# ADC1 register map
Vendor: Texas Instruments
Peripheral module from a debugger description file (folder am437x).
Registers are 32-bit, access per field, no defined reset value unless marked. A register's access mark holds for its fields unless they carry their own. Offsets are as the file gives them; lines under a group give offsets from that group; [hi:lo] are bit positions; {n}, {i} and the like mark numbered series; 'fields as' and 'values as' point back to an identical list; <NAME> marks a mode.

## ADC1
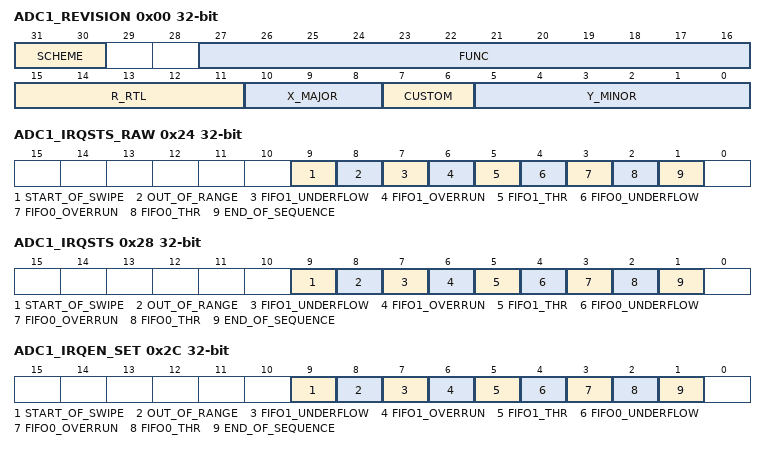
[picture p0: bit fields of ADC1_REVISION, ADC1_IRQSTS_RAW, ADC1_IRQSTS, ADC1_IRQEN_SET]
0x00 ADC1_REVISION ro
  [31:30] SCHEME — HL 0.8 scheme
  [27:16] FUNC — Functional Number
  [15:11] R_RTL — RTL revision. [[br]]Will vary depending on release.
  [10:8] X_MAJOR — Major revision.
  [7:6] CUSTOM — Custom revision.
  [5:0] Y_MINOR — Minor revision
0x10 ADC1_SYSCONFIG
  [3:2] IDLEMODE rw — [[br]]00 -> Force Idle (always acknowledges). [[br]]01 -> No Idle Mode (never acknowledges). [[br]]10 -> Smart-Idle Mode. [[br]]11 -> Reserved.
0x24 ADC1_IRQSTS_RAW
  [9] START_OF_SWIPE rw — [[br]]Write 0: No action. [[br]]Write 1: Set event (debug). [[br]]Read 0: No event pending. [[br]]Read 1: Event pending.
  [8] OUT_OF_RANGE rw — [[br]]Write 0: No action. [[br]]Write 1: Set event (debug). [[br]]Read 0: No event pending. [[br]]Read 1: Event pending.
  [7] FIFO1_UNDERFLOW rw — [[br]]Write 0: No action. [[br]]Write 1: Set event (debug). [[br]]Read 0: No event pending. [[br]]Read 1: Event pending.
  [6] FIFO1_OVERRUN rw — [[br]]Write 0: No action. [[br]]Write 1: Set event (debug). [[br]]Read 0: No event pending. [[br]]Read 1: Event pending.
  [5] FIFO1_THR rw — [[br]]Write 0: No action. [[br]]Write 1: Set event (debug). [[br]]Read 0: No event pending. [[br]]Read 1: Event pending.
  [4] FIFO0_UNDERFLOW rw — [[br]]Write 0: No action. [[br]]Write 1: Set event (debug). [[br]]Read 0: No event pending. [[br]]Read 1: Event pending.
  [3] FIFO0_OVERRUN rw — [[br]]Write 0: No action. [[br]]Write 1: Set event (debug). [[br]]Read 0: No event pending. [[br]]Read 1: Event pending.
  [2] FIFO0_THR rw — [[br]]Write 0: No action. [[br]]Write 1: Set event (debug). [[br]]Read 0: No event pending. [[br]]Read 1: Event pending.
  [1] END_OF_SEQUENCE rw — [[br]]Write 0: No action. [[br]]Write 1: Set event (debug). [[br]]Read 0: No event pending. [[br]]Read 1: Event pending.
0x28 ADC1_IRQSTS
  [9] START_OF_SWIPE rw — [[br]]Write 0: No action. [[br]]Read 0: No (enabled) event pending. [[br]]Read 1: Event pending. [[br]]Write 1: Clear (raw) event.
  [8] OUT_OF_RANGE rw — [[br]]Write 0: No action. [[br]]Read 0: No (enabled) event pending. [[br]]Read 1: Event pending. [[br]]Write 1: Clear (raw) event.
  [7] FIFO1_UNDERFLOW rw — [[br]]Write 0: No action. [[br]]Read 0: No (enabled) event pending. [[br]]Read 1: Event pending. [[br]]Write 1: Clear (raw) event.
  [6] FIFO1_OVERRUN rw — [[br]]Write 0: No action. [[br]]Read 0: No (enabled) event pending. [[br]]Read 1: Event pending. [[br]]Write 1: Clear (raw) event.
  [5] FIFO1_THR rw — [[br]]Write 0: No action. [[br]]Read 0: No (enabled) event pending. [[br]]Read 1: Event pending. [[br]]Write 1: Clear (raw) event.
  [4] FIFO0_UNDERFLOW rw — [[br]]Write 0: No action. [[br]]Read 0: No (enabled) event pending. [[br]]Read 1: Event pending. [[br]]Write 1: Clear (raw) event.
  [3] FIFO0_OVERRUN rw — [[br]]Write 0: No action. [[br]]Read 0: No (enabled) event pending. [[br]]Read 1: Event pending. [[br]]Write 1: Clear (raw) event.
  [2] FIFO0_THR rw — [[br]]Write 0: No action. [[br]]Read 0: No (enabled) event pending. [[br]]Read 1: Event pending. [[br]]Write 1: Clear (raw) event.
  [1] END_OF_SEQUENCE rw — [[br]]Write 0: No action. [[br]]Read 0: No (enabled) event pending. [[br]]Read 1: Event pending. [[br]]Write 1: Clear (raw) event.
0x2C ADC1_IRQEN_SET
  [9] START_OF_SWIPE rw — [[br]]Write 0: No action. [[br]]Read 0: Interrupt disabled (masked). [[br]]Read 1: Interrupt enabled. [[br]]Write 1: Enable interrupt.
  [8] OUT_OF_RANGE rw — [[br]]Write 0: No action. [[br]]Read 0: Interrupt disabled (masked). [[br]]Read 1: Interrupt enabled. [[br]]Write 1: Enable interrupt.
  [7] FIFO1_UNDERFLOW rw — [[br]]Write 0: No action. [[br]]Read 0: Interrupt disabled (masked). [[br]]Read 1: Interrupt enabled. [[br]]Write 1: Enable interrupt.
  [6] FIFO1_OVERRUN rw — [[br]]Write 0: No action. [[br]]Read 0: Interrupt disabled (masked). [[br]]Read 1: Interrupt enabled. [[br]]Write 1: Enable interrupt.
  [5] FIFO1_THR rw — [[br]]Write 0: No action. [[br]]Read 0: Interrupt disabled (masked). [[br]]Read 1: Interrupt enabled. [[br]]Write 1: Enable interrupt.
  [4] FIFO0_UNDERFLOW rw — [[br]]Write 0: No action. [[br]]Read 0: Interrupt disabled (masked). [[br]]Read 1: Interrupt enabled. [[br]]Write 1: Enable interrupt.
  [3] FIFO0_OVERRUN rw — [[br]]Write 0: No action. [[br]]Read 0: Interrupt disabled (masked). [[br]]Read 1: Interrupt enabled. [[br]]Write 1: Enable interrupt.
  [2] FIFO0_THR rw — [[br]]Write 0: No action. [[br]]Read 0: Interrupt disabled (masked). [[br]]Read 1: Interrupt enabled. [[br]]Write 1: Enable interrupt.
  [1] END_OF_SEQUENCE rw — [[br]]Write 0: No action. [[br]]Read 0: Interrupt disabled (masked). [[br]]Read 1: Interrupt enabled. [[br]]Write 1: Enable interrupt.
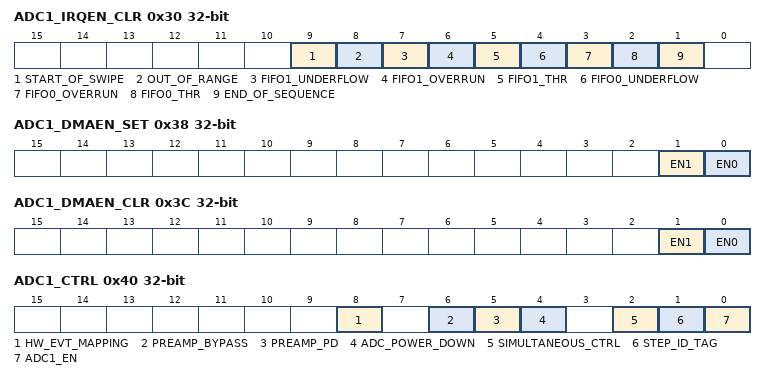
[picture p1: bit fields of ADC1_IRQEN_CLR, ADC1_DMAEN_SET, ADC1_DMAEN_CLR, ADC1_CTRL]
0x30 ADC1_IRQEN_CLR
  [9] START_OF_SWIPE rw — [[br]]Write 0: No action. [[br]]Read 0: Interrupt disabled (masked). [[br]]Read 1: Interrupt enabled. [[br]]Write 1: Disable interrupt.
  [8] OUT_OF_RANGE rw — [[br]]Write 0: No action. [[br]]Read 0: Interrupt disabled (masked). [[br]]Read 1: Interrupt enabled. [[br]]Write 1: Disable interrupt.
  [7] FIFO1_UNDERFLOW rw — [[br]]Write 0: No action. [[br]]Read 0: Interrupt disabled (masked). [[br]]Read 1: Interrupt enabled. [[br]]Write 1: Disable interrupt.
  [6] FIFO1_OVERRUN rw — [[br]]Write 0: No action. [[br]]Read 0: Interrupt disabled (masked). [[br]]Read 1: Interrupt enabled. [[br]]Write 1: Disable interrupt.
  [5] FIFO1_THR rw — [[br]]Write 0: No action. [[br]]Read 0: Interrupt disabled (masked). [[br]]Read 1: Interrupt enabled. [[br]]Write 1: Disable interrupt.
  [4] FIFO0_UNDERFLOW rw — [[br]]Write 0: No action. [[br]]Read 0: Interrupt disabled (masked). [[br]]Read 1: Interrupt enabled. [[br]]Write 1: Disable interrupt.
  [3] FIFO0_OVERRUN rw — [[br]]Write 0: No action. [[br]]Read 0: Interrupt disabled (masked). [[br]]Read 1: Interrupt enabled. [[br]]Write 1: Disable interrupt.
  [2] FIFO0_THR rw — [[br]]Write 0: No action. [[br]]Read 0: Interrupt disabled (masked). [[br]]Read 1: Interrupt enabled. [[br]]Write 1: Disable interrupt.
  [1] END_OF_SEQUENCE rw — [[br]]Write 0: No action. [[br]]Read 0: Interrupt disabled (masked). [[br]]Read 1: Interrupt enabled. [[br]]Write 1: Disable interrupt.
0x38 ADC1_DMAEN_SET rw
  [1] EN1 — Enable DMA request FIFO1. [[br]]Write 0: No action. [[br]]Read 0: DMA line disabled. [[br]]Read 1: DMA line enabled. [[br]]Write 1: Enable DMA line.
  [0] EN0 — Enable DMA request FIFO0. [[br]]Write 0: No action. [[br]]Read 0: DMA line disabled. [[br]]Read 1: DMA line enabled. [[br]]Write 1: Enable DMA line.
0x3C ADC1_DMAEN_CLR rw
  [1] EN1 — Disable DMA request FIFO1. [[br]]Write 0: No action. [[br]]Read 0: DMA line disabled. [[br]]Read 1: DMA line enabled. [[br]]Write 1: Disable DMA line.
  [0] EN0 — Disable DMA request FIFO0. [[br]]Write 0 : No action. [[br]]Read 0 : DMA line disabled. [[br]]Read 1: DMA line enabled. [[br]]Write 1: Disable DMA line.
0x40 ADC1_CTRL
  [8] HW_EVT_MAPPING rw — [[br]]0->Map hardware event to the start of swipe interrupt. [[br]]1->Map hardware event to hardware event input (external).
  [6] PREAMP_BYPASS rw — Analog input will bypass the PreAmplifier: 0: PreAmp is enabled by default. [[br]]1 : Write 1 to bypass PreAmp.
  [5] PREAMP_PD rw — PreAmp Power Down control. [[br]]0: PreAmp is powered up (default). [[br]]1 : Write 1 to power down PreAmp.
  [4] ADC_POWER_DOWN rw — ADC Power Down control. [[br]]0: AFE is powered up (default). [[br]]1 : Write 1 to power down AFE.
  [2] SIMULTANEOUS_CTRL rw — Enables Simultaneous Control of both AFEs. [[br]]0 -> Control only MCR_AFE. [[br]]1 -> Control both MCR_AFE and TSC_AFE. [[br]]See the Programmers/Usage guide section for Simultaneous Mode Features/Limitations.
  [1] STEP_ID_TAG rw — Writing 1 to this bit will store the Step ID number with the captured ADC data in the FIFO. [[br]]0: Write zeros. [[br]]1: Store the channel ID tag.
  [0] ADC1_EN rw — ADC1 module enable bit. [[br]]After programming all the steps and configuration registers, write a 1 to this bit to turn on ADC1. [[br]]Writing a 0 will disable the module (after the current conversion is completed).
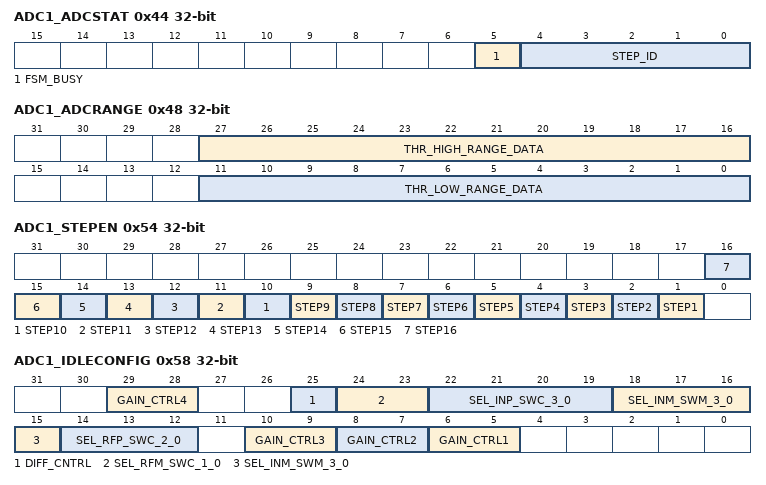
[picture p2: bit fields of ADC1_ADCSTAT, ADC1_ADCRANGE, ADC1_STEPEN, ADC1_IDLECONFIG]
0x44 ADC1_ADCSTAT ro
  [5] FSM_BUSY — Status of OCP FSM and ADC FSM. [[br]]0 idle. [[br]]1 - busy.
  [4:0] STEP_ID — Below are encoded values: 10000 Idle. [[br]]10001 Reserved. [[br]]00000 Step 1. [[br]]00001 Step 2. [[br]]00010 Step 3. [[br]]00011 Step 4. [[br]]00100 Step 5. [[br]]00101 Step 6. [[br]]00110 Step 7. [[br]]00111 Step 8. [[br]]01000 Step 9. [[br]]01001 Step 10. [[br]]01010 Step 11. [[br]]01011 Step 12. [[br]]01100 Step 13. [[br]]01101 Step 14. [[br]]01110 Step 15. [[br]]01111 Step 16.
0x48 ADC1_ADCRANGE
  [27:16] THR_HIGH_RANGE_DATA rw — Sampled ADC data is compared to this value. [[br]]If the interrupt is enabled, and if the sampled data is > value then interrupt is generated. [[br]]Each step can enable or disable this check.
  [11:0] THR_LOW_RANGE_DATA rw — Sampled ADC data is compared to this value. [[br]]If the interrupt is enabled, and if the sampled data is < value then interrupt is generated. [[br]]Each step can enable or disable this check.
0x4C ADC1_CLKDIV 16-bit rw
  [15:0] ADC_CLKDIV — The input ADC clock will be divided by this value and sent to the AFE. [[br]]Program to the value minus 1.
0x54 ADC1_STEPEN
  [n] STEP{n} rw (n=1..16) — Enable step {n}.
0x58 ADC1_IDLECONFIG
  [29:28] GAIN_CTRL4 rw — [[br]]00: Gain of 12. [[br]]01: Gain of 14. [[br]]10: Gain of 16. [[br]]11: Gain of 18.
  [25] DIFF_CNTRL rw — Differential Control Pin. [[br]]0 -> Single Ended. [[br]]1 -> Differential Pair Enable.
  [24:23] SEL_RFM_SWC_1_0 rw — SEL_RFM pins software configuration. [[br]]00 - VSSA. [[br]]01 - VSSA. [[br]]10 - VSSA. [[br]]11 ADCREFM.
  [22:19] SEL_INP_SWC_3_0 rw — SEL_INP pins software configuration. [[br]]0000 -> Channel 1. [[br]]0111 -> Channel 8. [[br]]1xxx -> ADCREFM.
  [18:15] SEL_INM_SWM_3_0 rw — SEL_INM pins for neg differential. [[br]]0000 -> Channel 1. [[br]]0111 -> Channel 8. [[br]]1xxx -> ADCREFM.
  [14:12] SEL_RFP_SWC_2_0 rw — SEL_RFP pins software configuration. [[br]]000 - VDDA. [[br]]001 - VDDA. [[br]]010 - VDDA. [[br]]011 - ADCREFP. [[br]]1xx - Reserved.
  [10:9] GAIN_CTRL3 rw — [[br]]00: Gain of 12. [[br]]01: Gain of 14. [[br]]10: Gain of 16. [[br]]11: Gain of 18.
  [8:7] GAIN_CTRL2 rw — [[br]]00: Gain of 12. [[br]]01: Gain of 14. [[br]]10: Gain of 16. [[br]]11: Gain of 18.
  [6:5] GAIN_CTRL1 rw — [[br]]00: Gain of 12. [[br]]01: Gain of 14. [[br]]10: Gain of 16. [[br]]11: Gain of 18.
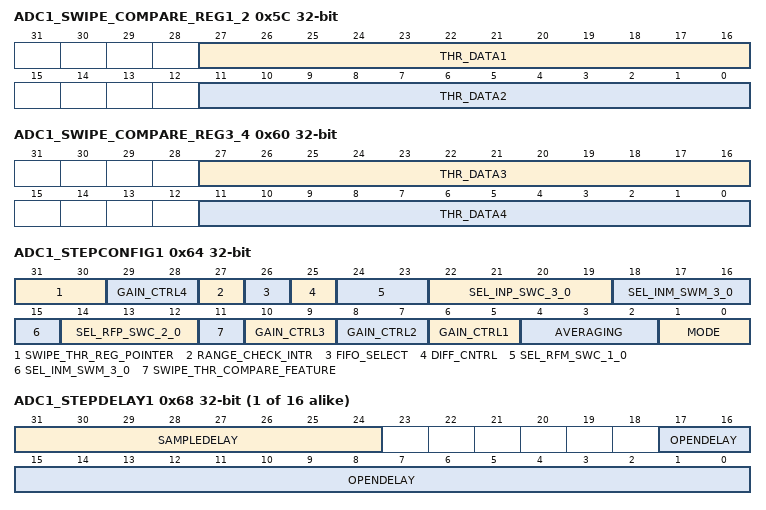
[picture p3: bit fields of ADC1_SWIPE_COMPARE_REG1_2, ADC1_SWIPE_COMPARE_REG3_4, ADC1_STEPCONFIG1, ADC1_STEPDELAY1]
0x5C ADC1_SWIPE_COMPARE_REG1_2
  [27:16] THR_DATA1 rw — Sampled ADC data is compared to this value. [[br]]If the swipe feature is enabled, and if the sampled data is >= value then data is saved in the FIFO (and also subsequent data is saved for all steps). [[br]]
  [11:0] THR_DATA2 rw — Sampled ADC data is compared to this value. [[br]]If the swipe feature is enabled, and if the sampled data is >= value then data is saved in the FIFO (and also subsequent data is saved for all steps). [[br]]
0x60 ADC1_SWIPE_COMPARE_REG3_4
  [27:16] THR_DATA3 rw — Sampled ADC data is compared to this value. [[br]]If the swipe feature is enabled, and if the sampled data is >= value then data is saved in the FIFO (and also subsequent data is saved for all steps). [[br]]
  [11:0] THR_DATA4 rw — Sampled ADC data is compared to this value. [[br]]If the swipe feature is enabled, and if the sampled data is >= value then data is saved in the FIFO (and also subsequent data is saved for all steps). [[br]]
0x64 ADC1_STEPCONFIG1 rw
  [31:30] SWIPE_THR_REG_POINTER — If the Swipe Data Compare feature is enabled (refer to bit 11) then: 00 Trigger using swipe threshold reg1. [[br]]01 Trigger using swipe threshold reg 2. [[br]]10 Trigger using swipe threshold reg 3. [[br]]11 Trigger using swipe threshold reg 4.
  [29:28] GAIN_CTRL4 — [[br]]00: Gain of 12. [[br]]01: Gain of 14. [[br]]10: Gain of 16. [[br]]11: Gain of 18.
  [27] RANGE_CHECK_INTR — [[br]]0 - disable out of range check. [[br]]1 - Compare adc data with range check register.
  [26] FIFO_SELECT — Sampled data will be stored in FIFO: [[br]]0 -> FIFO 0. [[br]]1 -> FIFO 1.
  [25] DIFF_CNTRL — Differential Control Pin. [[br]]0 -> Single Ended. [[br]]1 -> Differential Pair Enable.
  [24:23] SEL_RFM_SWC_1_0 — SEL_RFM pins software configuration. [[br]]00 - VSSA. [[br]]01 - VSSA. [[br]]10 - VSSA. [[br]]11 ADCREFM.
  [22:19] SEL_INP_SWC_3_0 — SEL_INP pins software configuration. [[br]]0000 -> Channel 1. [[br]]0111 -> Channel 8. [[br]]1xxx -> ADCREFM.
  [18:15] SEL_INM_SWM_3_0 — SEL_INM pins for neg differential. [[br]]0000 -> Channel 1. [[br]]0111 -> Channel 8. [[br]]1xxx -> ADCREFM.
  [14:12] SEL_RFP_SWC_2_0 — SEL_RFP pins software configuration. [[br]]000 - VDDA. [[br]]001 - VDDA. [[br]]010 - VDDA. [[br]]011 - ADCREFP. [[br]]1xx - Reserved.
  [11] SWIPE_THR_COMPARE_FEATURE — Set this bit to 1 to enable the swipe data comparing feature: [[br]]0: Feature is off (data is always saved). [[br]]1: Trigger feature is on [[br]] if adc data < swipe data threshold map pointer value then discard data[[br]] otherwise data is saved (and all future steps are saved) until mag_adc enable (bit 0) is turned off.
  [10:9] GAIN_CTRL3 — [[br]]00: Gain of 12. [[br]]01: Gain of 14. [[br]]10: Gain of 16. [[br]]11: Gain of 18.
  [8:7] GAIN_CTRL2 — [[br]]00: Gain of 12. [[br]]01: Gain of 14. [[br]]10: Gain of 16. [[br]]11: Gain of 18.
  [6:5] GAIN_CTRL1 — [[br]]00: Gain of 12. [[br]]01: Gain of 14. [[br]]10: Gain of 16. [[br]]11: Gain of 18.
  [4:2] AVERAGING — Number of samplings to average: [[br]]000 -> no average. [[br]]001 -> 2 samples average. [[br]]010 -> 4 samples average. [[br]]011 -> 8 samples average. [[br]]100 -> 16 samples average.
  [1:0] MODE — 00 Software enabled, one-shot. [[br]]01 Software enabled, continuous. [[br]]10 Hardware synchronized, one-shot. [[br]]11 Hardware synchronized, continuous.
{0x60+8i} ADC1_STEPDELAY{i} (i=1..16)
  [31:24] SAMPLEDELAY rw — This register will control the number of ADC clock cycles to sample (hold SoC high). [[br]]Any value programmed here will be added to the minimum requirement of 1 clock cycle.
  [17:0] OPENDELAY rw — Program the number of ADC clock cycles to wait after applying the step configuration registers and before sending the start of ADC conversion.
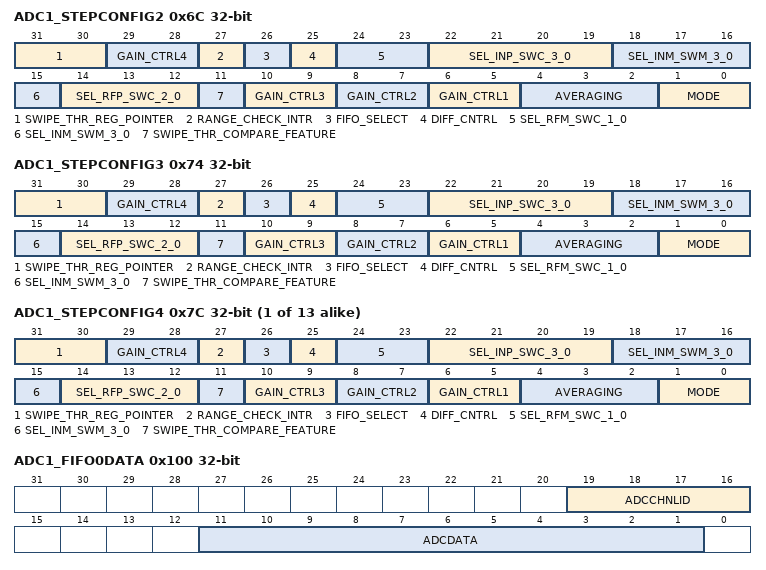
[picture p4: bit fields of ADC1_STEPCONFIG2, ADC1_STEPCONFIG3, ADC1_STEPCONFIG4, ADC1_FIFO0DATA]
0x6C ADC1_STEPCONFIG2 rw
  fields as ADC1_STEPCONFIG1
0x74 ADC1_STEPCONFIG3 rw
  [31:30] SWIPE_THR_REG_POINTER — If the Swipe Data Compare feature is enabled (refer to bit 11) then: 00 Trigger using swipe threshold reg1. [[br]]01 Trigger using swipe threshold reg 2. [[br]]10 Trigger using swipe threshold reg 3. [[br]]11 Trigger using swipe threshold reg 4.
  [29:28] GAIN_CTRL4 — [[br]]00: Gain of 12. [[br]]01: Gain of 14. [[br]]10: Gain of 16. [[br]]11: Gain of 18.
  [27] RANGE_CHECK_INTR — 0 disable out of range check. [[br]]1 - Compare adc data with range check register.
  [26] FIFO_SELECT — Sampled data will be stored in FIFO: [[br]]0 -> FIFO 0. [[br]]1 -> FIFO 1.
  [25] DIFF_CNTRL — Differential Control Pin. [[br]]0 -> Single Ended. [[br]]1 -> Differential Pair Enable.
  [24:23] SEL_RFM_SWC_1_0 — SEL_RFM pins software configuration. [[br]]00 - VSSA. [[br]]01 - VSSA. [[br]]10 - VSSA. [[br]]11 ADCREFM. [[br]]
  [22:19] SEL_INP_SWC_3_0 — SEL_INP pins software configuration. [[br]]0000 -> Channel 1. [[br]]0111 -> Channel 8. [[br]]1xxx -> ADCREFM. [[br]]
  [18:15] SEL_INM_SWM_3_0 — SEL_INM pins for neg differential. [[br]]0000 -> Channel 1. [[br]]0111 -> Channel 8. [[br]]1xxx -> ADCREFM.
  [14:12] SEL_RFP_SWC_2_0 — SEL_RFP pins software configuration. [[br]]000 - VDDA. [[br]]001 - VDDA. [[br]]010 - VDDA. [[br]]011 - ADCREFP. [[br]]1xx - Reserved. [[br]]
  [11] SWIPE_THR_COMPARE_FEATURE — Set this bit to 1 to enable the swipe data comparing feature: [[br]]0: Feature is off (data is always saved). [[br]]1: Trigger feature is on [[br]] if adc data < swipe data threshold map pointer value then discard data[[br]] otherwise data is saved (and all future steps are saved) until mag_adc enable (bit 0) is turned off.
  [10:9] GAIN_CTRL3 — [[br]]00: Gain of 12. [[br]]01: Gain of 14. [[br]]10: Gain of 16. [[br]]11: Gain of 18.
  [8:7] GAIN_CTRL2 — [[br]]00: Gain of 12. [[br]]01: Gain of 14. [[br]]10: Gain of 16. [[br]]11: Gain of 18.
  [6:5] GAIN_CTRL1 — [[br]]00: Gain of 12. [[br]]01: Gain of 14. [[br]]10: Gain of 16. [[br]]11: Gain of 18.
  [4:2] AVERAGING — Number of samplings to average: [[br]]000 -> no average. [[br]]001 -> 2 samples average. [[br]]010 -> 4 samples average. [[br]]011 -> 8 samples average. [[br]]100 -> 16 samples average.
  [1:0] MODE — 00 Software enabled, one-shot. [[br]]01 Software enabled, continuous. [[br]]10 Hardware synchronized, one-shot. [[br]]11 Hardware synchronized, continuous.
{0x5C+8i} ADC1_STEPCONFIG{i} rw (i=4..16)
  [31:30] SWIPE_THR_REG_POINTER — If the Swipe Data Compare feature is enabled (refer to bit 11) then: 00 Trigger using swipe threshold reg1. [[br]]01 Trigger using swipe threshold reg 2. [[br]]10 Trigger using swipe threshold reg 3. [[br]]11 Trigger using swipe threshold reg 4.
  [29:28] GAIN_CTRL4 — [[br]]00: Gain of 12. [[br]]01: Gain of 14. [[br]]10: Gain of 16. [[br]]11: Gain of 18.
  [27] RANGE_CHECK_INTR — 0 disable out of range check. [[br]]1 - Compare adc data with range check register.
  [26] FIFO_SELECT — Sampled data will be stored in FIFO: [[br]]0 -> FIFO 0. [[br]]1 -> FIFO 1.
  [25] DIFF_CNTRL — Differential Control Pin. [[br]]0 -> Single Ended. [[br]]1 -> Differential Pair Enable.
  [24:23] SEL_RFM_SWC_1_0 — SEL_RFM pins software configuration. [[br]]00 - VSSA. [[br]]01 - VSSA. [[br]]10 - VSSA. [[br]]11 ADCREFM. [[br]]
  [22:19] SEL_INP_SWC_3_0 — SEL_INP pins software configuration. [[br]]0000 -> Channel 1. [[br]]0111 -> Channel 8. [[br]]1xxx -> ADCREFM. [[br]]
  [18:15] SEL_INM_SWM_3_0 — SEL_INM pins for neg differential. [[br]]0000 -> Channel 1. [[br]]0111 -> Channel 8. [[br]]1xxx -> ADCREFM.
  [14:12] SEL_RFP_SWC_2_0 — SEL_RFP pins software configuration. [[br]]000 - VDDA. [[br]]001 - VDDA. [[br]]010 - VDDA. [[br]]011 - ADCREFP. [[br]]1xx - Reserved. [[br]]
  [11] SWIPE_THR_COMPARE_FEATURE — Set this bit to 1 to enable the swipe data comparing feature: [[br]]0: Feature is off (data is always saved). [[br]]1: Trigger feature is on[[br]] if adc data < swipe data threshold map pointer value then discard data[[br]] otherwise data is saved (and all future steps are saved) until mag_adc enable (bit 0) is turned off.
  [10:9] GAIN_CTRL3 — [[br]]00: Gain of 12. [[br]]01: Gain of 14. [[br]]10: Gain of 16. [[br]]11: Gain of 18.
  [8:7] GAIN_CTRL2 — [[br]]00: Gain of 12. [[br]]01: Gain of 14. [[br]]10: Gain of 16. [[br]]11: Gain of 18.
  [6:5] GAIN_CTRL1 — [[br]]00: Gain of 12. [[br]]01: Gain of 14. [[br]]10: Gain of 16. [[br]]11: Gain of 18.
  [4:2] AVERAGING — Number of samplings to average: [[br]]000 -> no average. [[br]]001 -> 2 samples average. [[br]]010 -> 4 samples average. [[br]]011 -> 8 samples average. [[br]]100 -> 16 samples average.
  [1:0] MODE — 00 Software enabled, one-shot. [[br]]01 Software enabled, continuous. [[br]]10 Hardware synchronized, one-shot. [[br]]11 Hardware synchronized, continuous.
0xE4 ADC1_FIFO0COUNT ro
  [6:0] WORDS_IN_FIFO0 — Number of words currently in the FIFO0.
0xE8 ADC1_FIFO0THR rw
  [5:0] FIFO0_THR_LEVEL — Program the desired FIFO0 data sample level to reach before generating interrupt to CPU (program to value minus 1).
0xEC ADC1_DMA0REQ rw
  [5:0] DMA_REQUEST_LEVEL — Number of words in FIFO0 before generating a DMA request (program to value minus 1).
0xF0 ADC1_FIFO1COUNT ro
  [6:0] WORDS_IN_FIFO1 — Number of words currently in the FIFO1.
0xF4 ADC1_FIFO1THR rw
  [5:0] FIFO1_THR_LEVEL — Program the desired FIFO1 data sample level to reach before generating interrupt to CPU (program to value minus 1).
0xF8 ADC1_DMA1REQ rw
  [5:0] DMA_REQUEST_LEVEL — Number of words in FIFO1 before generating a DMA request (program to value minus 1).
0x100 ADC1_FIFO0DATA ro
  [19:16] ADCCHNLID — Optional ID tag of channel that captured the data. [[br]]If tag option is disabled, these bits will be 0.
  [11:1] ADCDATA — 12 bit sampled ADC converted data value stored in FIFO0.
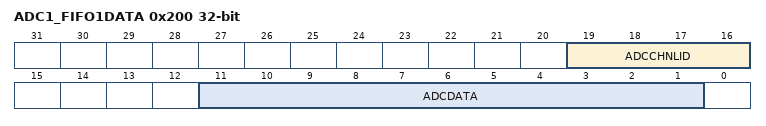
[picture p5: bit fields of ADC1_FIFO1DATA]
0x200 ADC1_FIFO1DATA ro
  [19:16] ADCCHNLID — Optional ID tag of channel that captured the data. [[br]]If tag option is disabled, these bits will be 0.
  [11:1] ADCDATA — 12 bit sampled ADC converted data value stored in FIFO1.
